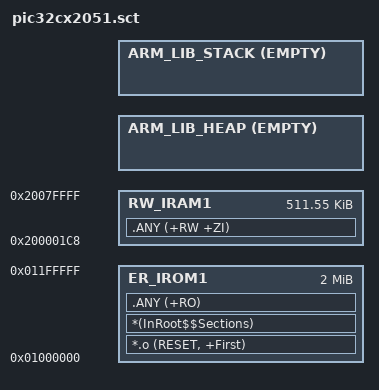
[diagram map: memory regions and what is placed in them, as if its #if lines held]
#! armcc -E
; *************************************************************
; *** Scatter-Loading Description File generated by uVision ***
; *************************************************************

; 16+97 vect 
#define VECTORS     113   

#if !defined(MBED_APP_START)
  #define MBED_APP_START 0x01000000
#endif

#if !defined(MBED_APP_SIZE)
  #define MBED_APP_SIZE 0x200000
#endif

#if !defined(MBED_RAM_START)
  #define MBED_RAM_START 0x20000000
#endif

#if !defined(MBED_RAM_SIZE)
  #define MBED_RAM_SIZE 0x80000
#endif

#if !defined(MBED_CONF_TARGET_BOOT_STACK_SIZE)
  #if defined(MBED_BOOT_STACK_SIZE)
    #define MBED_CONF_TARGET_BOOT_STACK_SIZE (MBED_BOOT_STACK_SIZE)
  #else
    #define MBED_CONF_TARGET_BOOT_STACK_SIZE 0x400
  #endif
#endif

; 8_byte_aligned(16+97 vect * 4 bytes) = (((0x1C4 * 4) + 7) & 0xFFFFFFF8) = 0x1C8
#define VECTORS_SIZE      0x1C8

#define RAM_FIXED_SIZE              (MBED_CONF_TARGET_BOOT_STACK_SIZE+VECTORS_SIZE)

LR_IROM1  MBED_APP_START  MBED_APP_SIZE  {    ; load region size_region

  ER_IROM1  MBED_APP_START  MBED_APP_SIZE  {  ; load address = execution address
   *.o (RESET, +First)
   *(InRoot$$Sections)
   .ANY (+RO)
  }
  
  RW_IRAM1  (MBED_RAM_START+VECTORS_SIZE)  (MBED_RAM_SIZE-VECTORS_SIZE)  {  ; RW data
   .ANY (+RW +ZI)
  }

  ARM_LIB_HEAP  AlignExpr(+0, 16)  EMPTY  (MBED_RAM_SIZE-RAM_FIXED_SIZE+MBED_RAM_START-AlignExpr(ImageLimit(RW_IRAM1), 16))  {
  }

  ARM_LIB_STACK  (MBED_RAM_START+MBED_RAM_SIZE)  EMPTY  -MBED_CONF_TARGET_BOOT_STACK_SIZE { ; stack
  }
}

